AUTOSAR XML (schema 00048)
package /HuaweiMDC/PlatformApplication/CameraAppApplication/CameraAppExcutable
  executable camera_app
    root sw component prototype camera_app: application-type=CameraAppApplicationSwComponent
package /HuaweiMDC/PlatformApplication/CameraAppApplication/CameraAppSwComponent
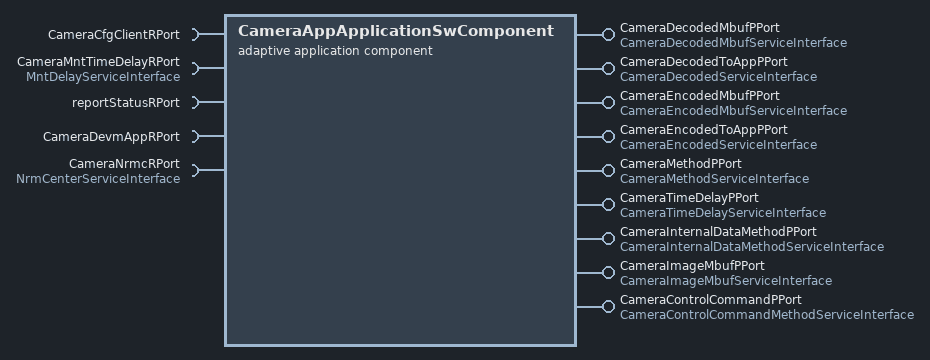
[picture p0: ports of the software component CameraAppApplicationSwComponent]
  adaptive application sw component type CameraAppApplicationSwComponent
    require port CameraCfgClientRPort
    5 x provide port:
      CameraDecodedMbufPPort: provided-interface=CameraDecodedMbufServiceInterface
      CameraDecodedToAppPPort: provided-interface=CameraDecodedServiceInterface
      CameraEncodedMbufPPort: provided-interface=CameraEncodedMbufServiceInterface
      CameraEncodedToAppPPort: provided-interface=CameraEncodedServiceInterface
      CameraMethodPPort: provided-interface=CameraMethodServiceInterface
    require port CameraMntTimeDelayRPort: required-interface=MntDelayServiceInterface
    provide port CameraTimeDelayPPort: provided-interface=CameraTimeDelayServiceInterface
    provide port CameraInternalDataMethodPPort: provided-interface=CameraInternalDataMethodServiceInterface
    require port reportStatusRPort
    require port CameraDevmAppRPort
    provide port CameraImageMbufPPort: provided-interface=CameraImageMbufServiceInterface
    require port CameraNrmcRPort: required-interface=NrmCenterServiceInterface
    provide port CameraControlCommandPPort: provided-interface=CameraControlCommandMethodServiceInterface
  composition sw component type camera_diag
    component diag_agent: type=diag_agent
    component camera_diag_cm: type=camera_diag
